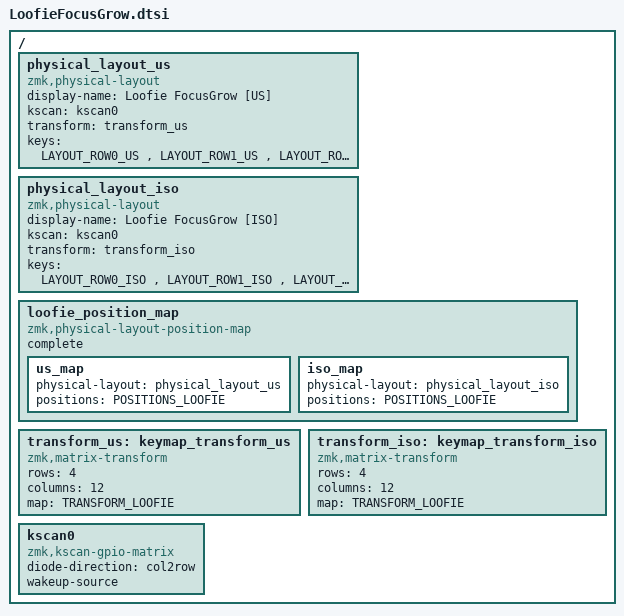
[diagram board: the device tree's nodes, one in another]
#include <physical_layouts.dtsi>
#include <dt-bindings/zmk/matrix_transform.h>
#include "LoofieFocusGrow_layout.h"

/ {
    /* ─── US Enter layout ─── */
    physical_layout_us: physical_layout_us {
        compatible = "zmk,physical-layout";
        display-name = "Loofie FocusGrow [US]";
        kscan = <&kscan0>;
        transform = <&transform_us>;
        keys = LAYOUT_ROW0_US
             , LAYOUT_ROW1_US
             , LAYOUT_ROW2
             , LAYOUT_ROW3
             ;
    };

    /* ─── ISO Enter layout ─── */
    physical_layout_iso: physical_layout_iso {
        compatible = "zmk,physical-layout";
        display-name = "Loofie FocusGrow [ISO]";
        kscan = <&kscan0>;
        transform = <&transform_iso>;
        keys = LAYOUT_ROW0_ISO
             , LAYOUT_ROW1_ISO
             , LAYOUT_ROW2
             , LAYOUT_ROW3
             ;
    };

    loofie_position_map {
        compatible = "zmk,physical-layout-position-map";
        complete;

        us_map: us_map {
            physical-layout = <&physical_layout_us>;
            positions = POSITIONS_LOOFIE;
        };

        iso_map: iso_map {
            physical-layout = <&physical_layout_iso>;
            positions = POSITIONS_LOOFIE;
        };
    };

    transform_us: keymap_transform_us {
        compatible = "zmk,matrix-transform";
        rows = <4>;
        columns = <12>;
        map = <TRANSFORM_LOOFIE>;
    };

    transform_iso: keymap_transform_iso {
        compatible = "zmk,matrix-transform";
        rows = <4>;
        columns = <12>;
        map = <TRANSFORM_LOOFIE>;
    };

    kscan0: kscan0 {
        compatible = "zmk,kscan-gpio-matrix";
        diode-direction = "col2row";
        wakeup-source;
    };
};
